# VPAC0_IVPAC_TOP_0_CFG_SLV_PAR_VPAC_VISS0_S_VBUSP_VISS_NSF4V_CFG_MMR_VBUSP_NSF4VCORE register map
Vendor: Texas Instruments
Peripheral module from a debugger description file (folder J722S).
Registers are 32-bit, read-write, reset values left out (the file's numbers can be read two ways) unless marked. A register's access mark holds for its fields unless they carry their own. Offsets are as the file gives them; lines under a group give offsets from that group; [hi:lo] are bit positions; {n}, {i} and the like mark numbered series; 'fields as' and 'values as' point back to an identical list; <NAME> marks a mode.

## VPAC0_IVPAC_TOP_0_CFG_SLV_PAR_VPAC_VISS0_S_VBUSP_VISS_NSF4V_CFG_MMR_VBUSP_NSF4VCORE
0x04 IVPAC_TOP_0__CFG_SLV__PAR_VPAC_VISS0__S_VBUSP__VISS_NSF4V__CFG__MMR__MMR_VBUSP__NSF4VCORE_REG_dbg — Diagnostic Register Control
  [5:0] RAM_MUX_CFG — Diagnostic Rd Wr access to Embedded RAM Selector Mux. This bit controls the mux select or which RAM and which section of that RAM are assessed via the VBUSP read of RAM. (This MMR is not shadowed)
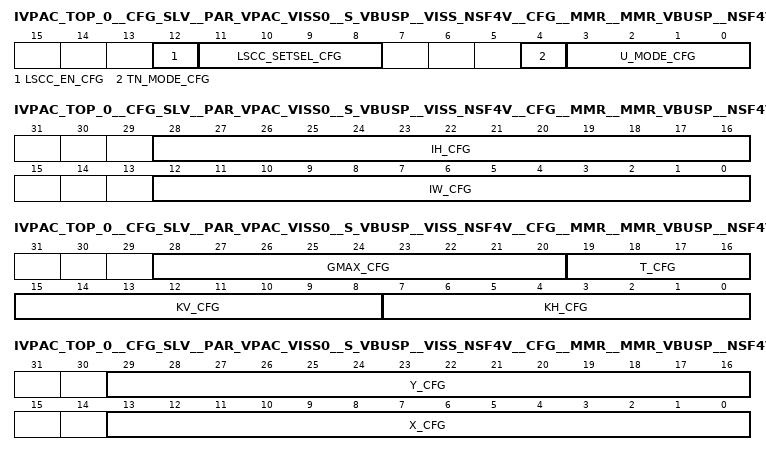
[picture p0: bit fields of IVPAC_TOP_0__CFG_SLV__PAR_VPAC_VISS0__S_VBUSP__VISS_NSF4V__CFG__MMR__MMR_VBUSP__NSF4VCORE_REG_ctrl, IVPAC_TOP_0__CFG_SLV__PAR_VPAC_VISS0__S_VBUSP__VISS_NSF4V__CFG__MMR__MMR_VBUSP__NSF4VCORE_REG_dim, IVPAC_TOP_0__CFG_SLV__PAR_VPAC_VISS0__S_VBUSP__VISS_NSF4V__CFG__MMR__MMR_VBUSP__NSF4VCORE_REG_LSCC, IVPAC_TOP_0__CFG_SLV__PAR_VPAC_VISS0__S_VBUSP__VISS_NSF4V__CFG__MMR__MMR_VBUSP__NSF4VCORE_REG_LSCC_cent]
0x08 IVPAC_TOP_0__CFG_SLV__PAR_VPAC_VISS0__S_VBUSP__VISS_NSF4V__CFG__MMR__MMR_VBUSP__NSF4VCORE_REG_ctrl — All modes are set here
  [12] LSCC_EN_CFG — enable Lens Shading Correction Compensation. When disabled, implments a unity gain
  [11:8] LSCC_SETSEL_CFG — bit per BAYER color component indicating which of two sets of 16 segment PWL Curve to use for LSCC. 0: use set0 1: use set1
  [4] TN_MODE_CFG — single bit controlling T_n calculation 0: use u_mode bits to indicate which LL2 to average and which bits to keep independent without averaging 1: independent no averaging
  [3:0] U_MODE_CFG — bit per BAYER color component indicating Decomp sub component 0: average with others 1: independent color component do not average for calculation of U Suppress. bit[0]:color 0 at (v=0, h=0) bit[1]:color 1 at (v=0, h=1) bit[2]:color 2 at (v=1, h=0) bit[3]:color 3 at (v=1, h=1)
0x0C IVPAC_TOP_0__CFG_SLV__PAR_VPAC_VISS0__S_VBUSP__VISS_NSF4V__CFG__MMR__MMR_VBUSP__NSF4VCORE_REG_dim — Input Output Frame dimensions in units of pixels. Same value for input and output
  [28:16] IH_CFG — (U13) input height in units of pixels minus 1.
  [12:0] IW_CFG — (U13) input width in units of pixels minus 1. Max usable value determined by populated line buffer RAM size
0x10 IVPAC_TOP_0__CFG_SLV__PAR_VPAC_VISS0__S_VBUSP__VISS_NSF4V__CFG__MMR__MMR_VBUSP__NSF4VCORE_REG_LSCC — Lens Shading Correction Compensation. First control register
  [28:20] GMAX_CFG — (U4.5) LSCC maximum gain. Any calculated value is clipped to this max value
  [19:16] T_CFG — (U4) LSCC radius dynamic range select. T is the right shift amount prior to MSB clip.
  [15:8] KV_CFG — (U2.6) LSCC horizontal or Y Gain for elliptical lens
  [7:0] KH_CFG — (U2.6) LSCC vertical or X Gain for elliptical lens
0x14 IVPAC_TOP_0__CFG_SLV__PAR_VPAC_VISS0__S_VBUSP__VISS_NSF4V__CFG__MMR__MMR_VBUSP__NSF4VCORE_REG_LSCC_cent — Lens Shading Correction Compensation. Programmable Center of frame
  [29:16] Y_CFG — (S14) Vertical (Y) position of lens center. Negative value supports the case where processed frame starts after the center. HW supports center config with below constraint. if (Y_cfg &#60; 0) # negative DIM.ih_cfg + abs(Y_cfg) &#60; 8K else # positive Y_cfg &#60; 8K
  [13:0] X_CFG — (S14) Horizontal (X) position of lens center. Negative value supports the case where processed frame starts after the center. HW supports center config with below constraint. if (X_cfg &#60; 0) # negative DIM.iw_cfg + abs(X_cfg) &#60; 8K else # positive X_cfg &#60; 8K
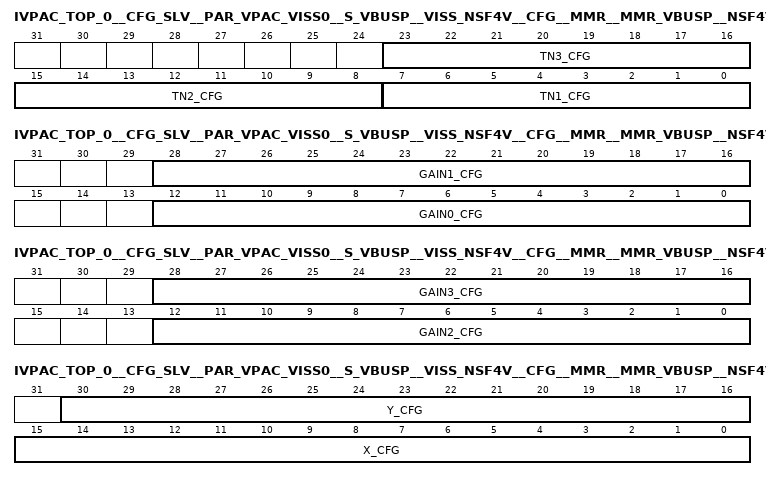
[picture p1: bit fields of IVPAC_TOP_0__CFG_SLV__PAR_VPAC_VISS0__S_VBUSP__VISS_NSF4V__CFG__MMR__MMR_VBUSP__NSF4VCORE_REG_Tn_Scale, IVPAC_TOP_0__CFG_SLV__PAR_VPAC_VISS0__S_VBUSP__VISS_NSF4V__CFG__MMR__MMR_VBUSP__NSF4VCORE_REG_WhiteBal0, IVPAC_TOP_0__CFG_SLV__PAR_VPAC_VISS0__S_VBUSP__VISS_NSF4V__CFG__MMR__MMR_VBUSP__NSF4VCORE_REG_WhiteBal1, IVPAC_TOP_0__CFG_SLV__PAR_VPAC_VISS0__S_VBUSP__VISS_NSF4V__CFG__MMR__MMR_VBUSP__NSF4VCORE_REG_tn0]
0x1C IVPAC_TOP_0__CFG_SLV__PAR_VPAC_VISS0__S_VBUSP__VISS_NSF4V__CFG__MMR__MMR_VBUSP__NSF4VCORE_REG_Tn_Scale — Tn scaling factor multiplied by all 4 color components Tn after 12 segment PWL. Different scaling factor per level
  [23:16] TN3_CFG — (U3.5) Level3. Sub-bands 7, 8, 9
  [15:8] TN2_CFG — (U3.5) Level2. Sub-bands 4, 5, 6
  [7:0] TN1_CFG — (U3.5) Level1. Sub-bands 0, 1, 2
0x20 IVPAC_TOP_0__CFG_SLV__PAR_VPAC_VISS0__S_VBUSP__VISS_NSF4V__CFG__MMR__MMR_VBUSP__NSF4VCORE_REG_U_knee — U suppression curve knee. Same knee value for all 9 levels x 4 color components.
  [5:0] U_KNEE_CFG — (U0.6) U Suppress curve knee. X (LL2) value which separates constant suppression of 1.0 from linear suppression.
0x24 IVPAC_TOP_0__CFG_SLV__PAR_VPAC_VISS0__S_VBUSP__VISS_NSF4V__CFG__MMR__MMR_VBUSP__NSF4VCORE_REG_WhiteBal0 — White Balance Gain (Part0). Separate Gain for each of 4 colors
  [28:16] GAIN1_CFG — (U4.9) Gain for color 1
  [12:0] GAIN0_CFG — (U4.9) Gain for color 0
0x28 IVPAC_TOP_0__CFG_SLV__PAR_VPAC_VISS0__S_VBUSP__VISS_NSF4V__CFG__MMR__MMR_VBUSP__NSF4VCORE_REG_WhiteBal1 — White Balance Gain (Part1). Separate Gain for each of 4 colors
  [28:16] GAIN3_CFG — (U4.9) Gain for color 3
  [12:0] GAIN2_CFG — (U4.9) Gain for color 2
0x60 IVPAC_TOP_0__CFG_SLV__PAR_VPAC_VISS0__S_VBUSP__VISS_NSF4V__CFG__MMR__MMR_VBUSP__NSF4VCORE_REG_tn0 — T_n 12 segment piecewise linear curve Part0 (4 color x 12 segment)
  [30:16] Y_CFG — (U15) Y (U) value. T_n resulting value from lookup. Starting point from which SLOPE will linearly calculate between X Y points
  [15:0] X_CFG — (U16) X (LL2) value. LL2 averaged input value into lookup rounded down to nearest X value. (X0 programmed value is unused and defaults to a value of 0 in hardware implementation)
0x64 IVPAC_TOP_0__CFG_SLV__PAR_VPAC_VISS0__S_VBUSP__VISS_NSF4V__CFG__MMR__MMR_VBUSP__NSF4VCORE_REG_tn1 — T_n 12 segment piecewise linear curve Part1 (4 color x 12 segment)
  [15:0] S_CFG — (S5.11) S value. Slope value used calculated linear interpolation between X Y points
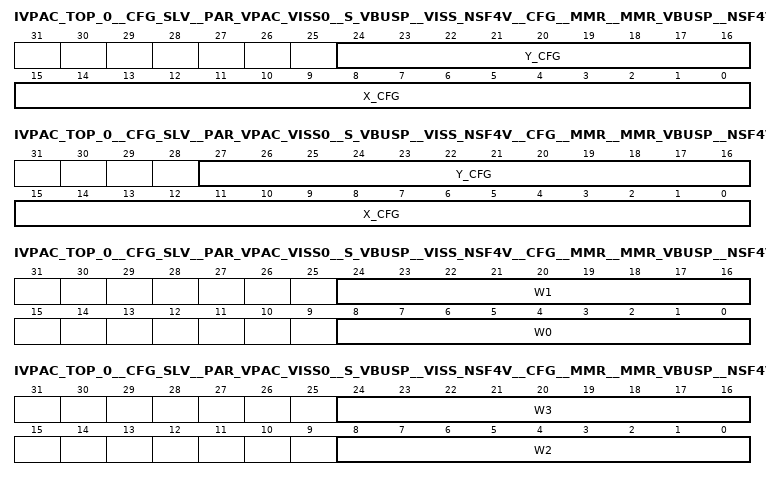
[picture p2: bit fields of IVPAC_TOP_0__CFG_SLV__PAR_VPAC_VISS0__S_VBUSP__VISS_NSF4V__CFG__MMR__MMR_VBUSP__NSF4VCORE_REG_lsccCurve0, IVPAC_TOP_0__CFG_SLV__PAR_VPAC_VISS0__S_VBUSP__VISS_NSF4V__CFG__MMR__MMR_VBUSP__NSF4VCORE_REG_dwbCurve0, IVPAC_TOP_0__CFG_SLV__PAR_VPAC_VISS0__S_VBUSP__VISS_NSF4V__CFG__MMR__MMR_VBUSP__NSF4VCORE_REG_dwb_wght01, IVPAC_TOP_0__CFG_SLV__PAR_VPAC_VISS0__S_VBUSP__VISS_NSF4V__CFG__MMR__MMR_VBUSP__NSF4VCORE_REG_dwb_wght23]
0x200 IVPAC_TOP_0__CFG_SLV__PAR_VPAC_VISS0__S_VBUSP__VISS_NSF4V__CFG__MMR__MMR_VBUSP__NSF4VCORE_REG_lsccCurve0 — LSCC 16 segment piecewise linear curve Part0 (2 set x 16 segment)
  [24:16] Y_CFG — (U15.0) Y (U) value. LSCC Gain resulting value from lookup. Starting point from which SLOPE will linearly calculate between X Y points
  [15:0] X_CFG — (U16) X (normalized radius from center) value. Input rounded down to nearest X value. (X0 programmed value is unused and defaults to a value of 0 in hardware implementation)
0x204 IVPAC_TOP_0__CFG_SLV__PAR_VPAC_VISS0__S_VBUSP__VISS_NSF4V__CFG__MMR__MMR_VBUSP__NSF4VCORE_REG_lsccCurve1 — LSCC 16 segment piecewise linear curve Part1 (2 set x 16 segment)
  fields as IVPAC_TOP_0__CFG_SLV__PAR_VPAC_VISS0__S_VBUSP__VISS_NSF4V__CFG__MMR__MMR_VBUSP__NSF4VCORE_REG_tn1
0x3F0 IVPAC_TOP_0__CFG_SLV__PAR_VPAC_VISS0__S_VBUSP__VISS_NSF4V__CFG__MMR__MMR_VBUSP__NSF4VCORE_REG_DWB_CNTL — Dynamic White Balance Control Register
  [0] DWB_EN — Dynamic White Balance Enable
0x400 IVPAC_TOP_0__CFG_SLV__PAR_VPAC_VISS0__S_VBUSP__VISS_NSF4V__CFG__MMR__MMR_VBUSP__NSF4VCORE_REG_dwbCurve0 — Dynamic WB 8 segment piecewise linear curve Part0. 4 color x 8 segment
  [27:16] Y_CFG — U12Q8 Y Reference value from the segment. Starting point from which SLOPE will linearly calculate between X Y points
  [15:0] X_CFG — U16 X Intesity value. X0 programmed value is unused and defaults to a value of 0 in hardware implementation
0x404 IVPAC_TOP_0__CFG_SLV__PAR_VPAC_VISS0__S_VBUSP__VISS_NSF4V__CFG__MMR__MMR_VBUSP__NSF4VCORE_REG_dwbCurve1 — Dynamic WB 8 segment piecewise linear curve Part1 (4 color x 8 segment)
  [15:0] S_CFG — S16Q12 Slope value for the segment. Slope value used calculated linear interpolation between X Y points
0x500 IVPAC_TOP_0__CFG_SLV__PAR_VPAC_VISS0__S_VBUSP__VISS_NSF4V__CFG__MMR__MMR_VBUSP__NSF4VCORE_REG_dwb_wght01 — Weights to calculate intensity
  [24:16] W1 — U9Q8 Weight1
  [8:0] W0 — U9Q8 Weight0
0x504 IVPAC_TOP_0__CFG_SLV__PAR_VPAC_VISS0__S_VBUSP__VISS_NSF4V__CFG__MMR__MMR_VBUSP__NSF4VCORE_REG_dwb_wght23 — Weights to calculate intensity
  [24:16] W3 — U9Q8 Weight3
  [8:0] W2 — U9Q8 Weight2
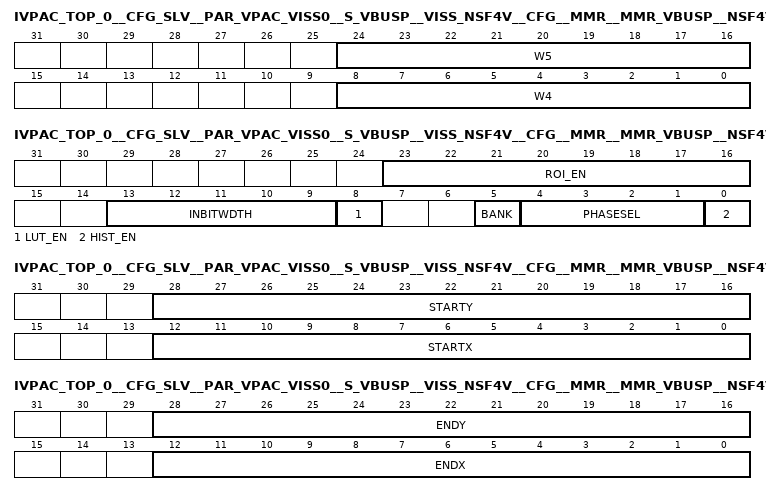
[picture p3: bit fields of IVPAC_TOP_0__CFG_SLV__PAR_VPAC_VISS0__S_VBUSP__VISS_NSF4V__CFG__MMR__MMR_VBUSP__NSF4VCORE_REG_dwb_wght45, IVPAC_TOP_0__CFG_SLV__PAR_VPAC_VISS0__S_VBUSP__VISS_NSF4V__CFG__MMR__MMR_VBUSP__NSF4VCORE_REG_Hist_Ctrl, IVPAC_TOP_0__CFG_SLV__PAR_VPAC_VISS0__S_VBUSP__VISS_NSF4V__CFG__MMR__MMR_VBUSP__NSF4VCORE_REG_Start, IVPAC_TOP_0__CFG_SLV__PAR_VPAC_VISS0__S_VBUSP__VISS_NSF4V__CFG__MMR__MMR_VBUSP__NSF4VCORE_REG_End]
0x508 IVPAC_TOP_0__CFG_SLV__PAR_VPAC_VISS0__S_VBUSP__VISS_NSF4V__CFG__MMR__MMR_VBUSP__NSF4VCORE_REG_dwb_wght45 — Weights to calculate intensity
  [24:16] W5 — U9Q8 Weight5
  [8:0] W4 — U9Q8 Weight4
0x5F0 IVPAC_TOP_0__CFG_SLV__PAR_VPAC_VISS0__S_VBUSP__VISS_NSF4V__CFG__MMR__MMR_VBUSP__NSF4VCORE_REG_Hist_Ctrl — Has control parameters related to Raw Domain Histogram
  [23:16] ROI_EN — Enable for ROIs. Each bit corresponds to one ROI. bit[x] to ROI[x]. Use lower index regions if less than 8 regions are needed.
  [13:9] INBITWDTH — BitWidth of the input image, values greater than 16 will be treated as 16 and values less than 12 will be treated as 12
  [8] LUT_EN — 0->Use shift(bitwidth-12), 1->Use LUT
  [5] BANK — Bank attached to Histogram HW Datapath. Shadowed and internal control is updated outisde of active frame 0 -> HW access Bank0 & Cfg MMR access Bank1 1 -> HW access Bank1 & Cfg MMR access Bank0.
  [4:1] PHASESEL — Histogram Phase select enable; one bit for each color channel. Up to 2 bits can be enabled; only bit can be enabled per line. bit[0]:color 0 at (v=0, h=0) bit[1]:color 1 at (v=0, h=1) bit[2]:color 2 at (v=1, h=0) bit[3]:color 3 at (v=1, h=1)
  [0] HIST_EN — Raw domain Histogram Enable. When enbaled minimum frame width has to be 128
0x600 IVPAC_TOP_0__CFG_SLV__PAR_VPAC_VISS0__S_VBUSP__VISS_NSF4V__CFG__MMR__MMR_VBUSP__NSF4VCORE_REG_Start — Start Pixel location for the region
  [28:16] STARTY — Valid line start Vertically. Needs to be even. Minimum is 2 and should be greater than previous region EndY
  [12:0] STARTX — Valid pixel start Horizontally. Has to be even
0x604 IVPAC_TOP_0__CFG_SLV__PAR_VPAC_VISS0__S_VBUSP__VISS_NSF4V__CFG__MMR__MMR_VBUSP__NSF4VCORE_REG_End — End Pixel location for the region
  [28:16] ENDY — Valid line end Vertically. Min region height is 8 and region height has to be even
  [12:0] ENDX — Valid pixel end Horizontally. Min region width is 8 and region width has to be even
